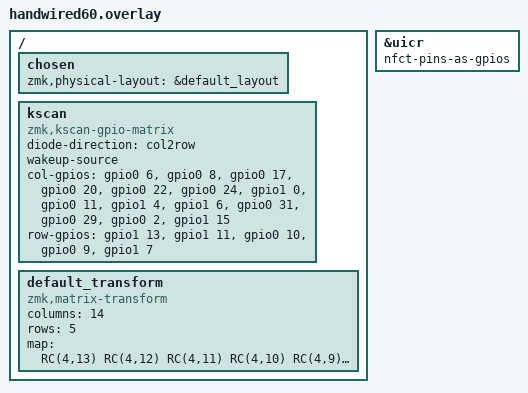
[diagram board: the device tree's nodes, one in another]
// This file was generated from a template. Edit it to match your keyboard.
// See https://zmk.dev/docs/development/hardware-integration/new-shield for more
// instructions.

#include <dt-bindings/zmk/matrix_transform.h>

#include "handwired60-layouts.dtsi"

/ {
    chosen {
        zmk,physical-layout = &default_layout;
    };

    kscan: kscan {
        // If the hardware does not use a switch matrix, change this to the
        // appropriate driver and update the properties below to match.
        // See https://zmk.dev/docs/config/kscan for supported key scan drivers.
        compatible = "zmk,kscan-gpio-matrix";
        // Set this to "col2row" or "row2col" to match the hardware. If using
        // "row2col", change the col-gpios to (GPIO_ACTIVE_HIGH | GPIO_PULL_DOWN)
        // and the row-gpios to GPIO_ACTIVE_HIGH.



        diode-direction = "col2row";
        wakeup-source;

        // Replace these comments with the GPIO pins in the matrix.
        // See https://zmk.dev/docs/development/hardware-integration/new-shield#shield-overlays
        /* Colonnes C0 à C13 */
        col-gpios =
            <&gpio0  6 GPIO_ACTIVE_HIGH>, /* C0  - P0.06 */
            <&gpio0  8 GPIO_ACTIVE_HIGH>, /* C1  - P0.08 */
            <&gpio0 17 GPIO_ACTIVE_HIGH>, /* C2  - P0.17 */
            <&gpio0 20 GPIO_ACTIVE_HIGH>, /* C3  - P0.20 */
            <&gpio0 22 GPIO_ACTIVE_HIGH>, /* C4  - P0.22 */
            <&gpio0 24 GPIO_ACTIVE_HIGH>, /* C5  - P0.24 */
            <&gpio1  0 GPIO_ACTIVE_HIGH>, /* C6  - P1.00 */
            <&gpio0 11 GPIO_ACTIVE_HIGH>, /* C7  - P0.11 */
            <&gpio1  4 GPIO_ACTIVE_HIGH>, /* C8  - P1.04 */
            <&gpio1  6 GPIO_ACTIVE_HIGH>, /* C9  - P1.06 */
            <&gpio0 31 GPIO_ACTIVE_HIGH>, /* C10 - P0.31 */
            <&gpio0 29 GPIO_ACTIVE_HIGH>, /* C11 - P0.29 */
            <&gpio0  2 GPIO_ACTIVE_HIGH>, /* C12 - P0.02 */
            <&gpio1 15 GPIO_ACTIVE_HIGH>; /* C13 - P1.15 */

            /* Lignes R0 à R4 */
            row-gpios =
                <&gpio1 13 (GPIO_ACTIVE_HIGH | GPIO_PULL_DOWN)>, /* R0 - P1.13 */
                <&gpio1 11 (GPIO_ACTIVE_HIGH | GPIO_PULL_DOWN)>, /* R1 - P1.11*/
                <&gpio0 10 (GPIO_ACTIVE_HIGH | GPIO_PULL_DOWN)>, /* R2 - P0.10*/
                <&gpio0  9 (GPIO_ACTIVE_HIGH | GPIO_PULL_DOWN)>, /* R3 - P0.09*/
                <&gpio1  7 (GPIO_ACTIVE_HIGH | GPIO_PULL_DOWN)>; /* R4 - P1.07*/

};

    default_transform: default_transform {
        // See https://zmk.dev/docs/development/hardware-integration/new-shield#matrix-transform
        // for how to configure this
        compatible = "zmk,matrix-transform";
        columns = <14>;
        rows = <5>;

        map = <

            /* R4 - Rangée supérieure */
            RC(4,13) /* S64 */
            RC(4,12) /* S63 */
            RC(4,11) /* S62 */
            RC(4,10) /* S61 */
            RC(4,9) /* S60 */
            RC(4,8) /* S59 */
            RC(4,7) /* S58 */
            RC(4,6) /* S57 */
            RC(4,5) /* S56 */
            RC(4,4) /* S55 */
            RC(4,3) /* S54 */
            RC(4,2) /* S53 */
            RC(4,1) /* S52 */
            RC(4,0) /* S51 */

            /* R3 - Deuxième rangée */
            RC(3,13) /* S50 */
            RC(3,12) /* S49 */
            RC(3,11) /* S48 */
            RC(3,10) /* S47 */
            RC(3,9) /* S46 */
            RC(3,8) /* S45 */
            RC(3,7) /* S44 */
            RC(3,6) /* S43 */
            RC(3,5) /* S42 */
            RC(3,4) /* S41 */
            RC(3,3) /* S40 */
            RC(3,2) /* S39 */
            RC(3,1) /* S38 */
            RC(3,0) /* S37 */

            /* R2 - Troisième rangée */ 

            RC(2,13) /* S36 */
            RC(2,12) /* S35 */
            RC(2,11) /* S34 */
            RC(2,10) /* S33 */
            RC(2,9) /* S32 */
            RC(2,8) /* S31 */
            RC(2,7) /* S30 */
            RC(2,6) /* S29 */
            RC(2,5) /* S28 */
            RC(2,4) /* S27 */
            RC(2,3) /* S26 */
            RC(2,2) /* S25 */
            RC(2,0) /* S24 */

            /* R1 - Quatrième rangée */

            RC(1,13) /* S23 */
            RC(1,12) /* S22 */
            RC(1,11) /* S21 */
            RC(1,10) /* S20 */
            RC(1,9) /* S19 */
            RC(1,8) /* S18 */
            RC(1,7) /* S17 */
            RC(1,6) /* S16 */
            RC(1,5) /* S15 */
            RC(1,4) /* S14 */
            RC(1,3) /* S13 */
            RC(1,2) /* S12 */
            RC(1,1) /* S11 */
            RC(1,0) /* S10 */

            /* R0 - Dernière rangée */

            RC(0,13) /* S09 */
            RC(0,12) /* S08 */
            RC(0,11) /* S07 */
            RC(0,8) /* S06 */
            RC(0,4) /* S05 */
            RC(0,3) /* S04 */
            RC(0,2) /* S03 */
            RC(0,1) /* S02 */
            RC(0,0) /* S01 */
            
        >;
    };
};


/* Autoriser l'utilisation des broches NFC comme GPIO */
&uicr {
    nfct-pins-as-gpios;
};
